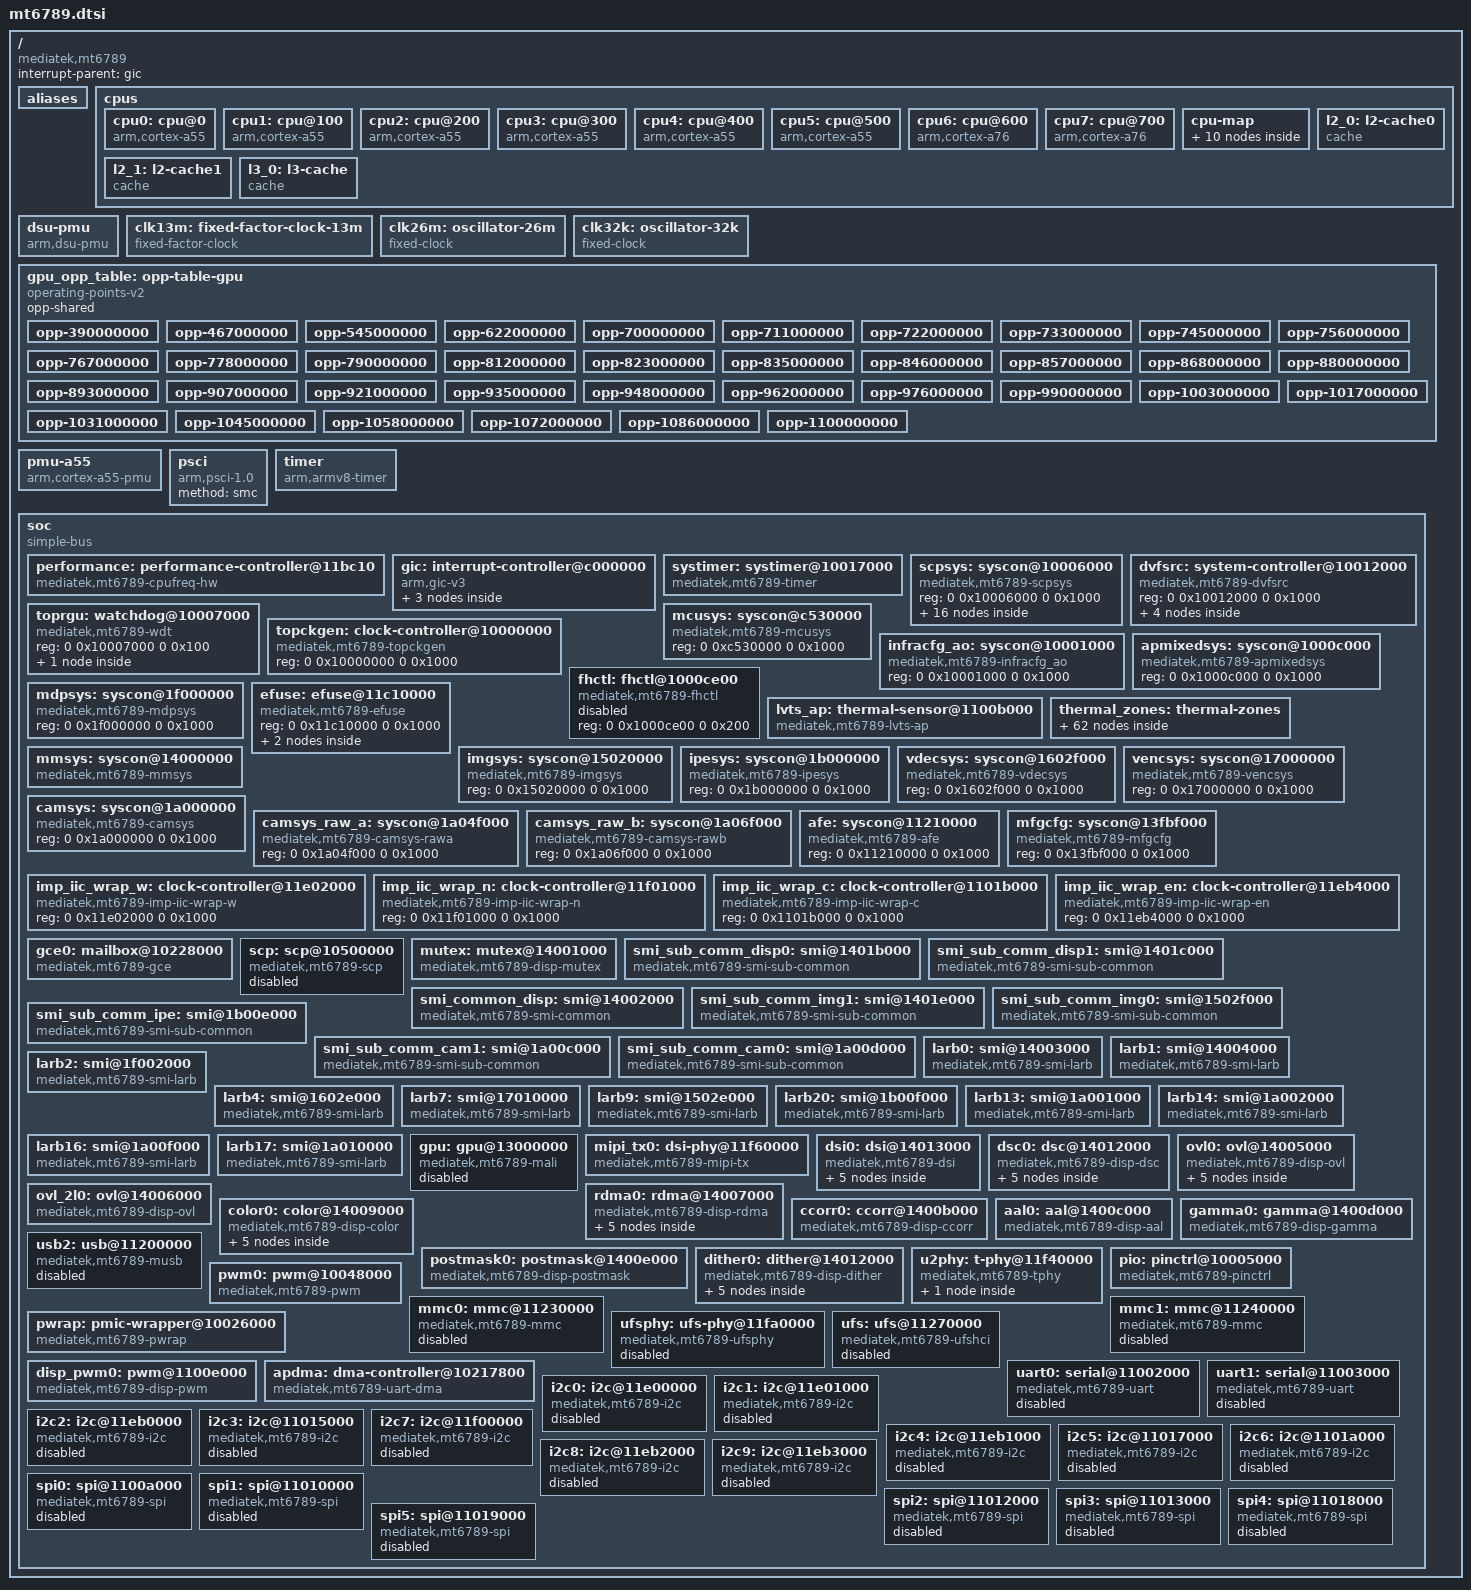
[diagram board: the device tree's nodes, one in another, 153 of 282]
// SPDX-License-Identifier: GPL-2.0
/*
 * Device Tree Source for Mediatek MT6789
 *
 * Copyright (c) 2025 Arseniy Velikanov <me@adomerle.pw>
 */
#include <dt-bindings/interrupt-controller/arm-gic.h>
#include <dt-bindings/interrupt-controller/irq.h>
#include <dt-bindings/phy/phy.h>

#include <dt-bindings/clock/mediatek,mt6789-clk.h>
#include <dt-bindings/power/mediatek,mt6789-power.h>
#include <dt-bindings/reset/mediatek,mt6789-resets.h>
#include <dt-bindings/gce/mediatek,mt6789-gce.h>
#include <dt-bindings/memory/mediatek,mt6789-memory-port.h>
#include <dt-bindings/thermal/thermal.h>
#include <dt-bindings/thermal/mediatek,lvts-thermal.h>

/ {
	compatible = "mediatek,mt6789";
	interrupt-parent = <&gic>;
	#address-cells = <2>;
	#size-cells = <2>;

	aliases {
		i2c0 = &i2c0;
		i2c1 = &i2c1;
		i2c2 = &i2c2;
		i2c3 = &i2c3;
		i2c4 = &i2c4;
		i2c5 = &i2c5;
		i2c6 = &i2c6;
		i2c7 = &i2c7;
		i2c8 = &i2c8;
		i2c9 = &i2c9;
	};

	cpus {
		#address-cells = <1>;
		#size-cells = <0>;

		cpu0: cpu@0 {
			device_type = "cpu";
			compatible = "arm,cortex-a55";
			reg = <0x000>;
			enable-method = "psci";
			clock-frequency = <2000000000>;
			capacity-dmips-mhz = <578>;
			performance-domains = <&performance 0>;
			i-cache-size = <32768>;
			i-cache-line-size = <64>;
			i-cache-sets = <128>;
			d-cache-size = <32768>;
			d-cache-line-size = <64>;
			d-cache-sets = <128>;
			next-level-cache = <&l2_0>;
			#cooling-cells = <2>;
		};

		cpu1: cpu@100 {
			device_type = "cpu";
			compatible = "arm,cortex-a55";
			reg = <0x100>;
			enable-method = "psci";
			clock-frequency = <2000000000>;
			capacity-dmips-mhz = <578>;
			performance-domains = <&performance 0>;
			i-cache-size = <32768>;
			i-cache-line-size = <64>;
			i-cache-sets = <128>;
			d-cache-size = <32768>;
			d-cache-line-size = <64>;
			d-cache-sets = <128>;
			next-level-cache = <&l2_0>;
			#cooling-cells = <2>;
		};

		cpu2: cpu@200 {
			device_type = "cpu";
			compatible = "arm,cortex-a55";
			reg = <0x200>;
			enable-method = "psci";
			clock-frequency = <2000000000>;
			capacity-dmips-mhz = <578>;
			performance-domains = <&performance 0>;
			i-cache-size = <32768>;
			i-cache-line-size = <64>;
			i-cache-sets = <128>;
			d-cache-size = <32768>;
			d-cache-line-size = <64>;
			d-cache-sets = <128>;
			next-level-cache = <&l2_0>;
			#cooling-cells = <2>;
		};

		cpu3: cpu@300 {
			device_type = "cpu";
			compatible = "arm,cortex-a55";
			reg = <0x300>;
			enable-method = "psci";
			clock-frequency = <2000000000>;
			capacity-dmips-mhz = <578>;
			performance-domains = <&performance 0>;
			i-cache-size = <32768>;
			i-cache-line-size = <64>;
			i-cache-sets = <128>;
			d-cache-size = <32768>;
			d-cache-line-size = <64>;
			d-cache-sets = <128>;
			next-level-cache = <&l2_0>;
			#cooling-cells = <2>;
		};

		cpu4: cpu@400 {
			device_type = "cpu";
			compatible = "arm,cortex-a55";
			reg = <0x400>;
			enable-method = "psci";
			clock-frequency = <2000000000>;
			capacity-dmips-mhz = <578>;
			performance-domains = <&performance 0>;
			i-cache-size = <32768>;
			i-cache-line-size = <64>;
			i-cache-sets = <128>;
			d-cache-size = <32768>;
			d-cache-line-size = <64>;
			d-cache-sets = <128>;
			next-level-cache = <&l2_0>;
			#cooling-cells = <2>;
		};

		cpu5: cpu@500 {
			device_type = "cpu";
			compatible = "arm,cortex-a55";
			reg = <0x500>;
			enable-method = "psci";
			clock-frequency = <2000000000>;
			capacity-dmips-mhz = <578>;
			performance-domains = <&performance 0>;
			i-cache-size = <32768>;
			i-cache-line-size = <64>;
			i-cache-sets = <128>;
			d-cache-size = <32768>;
			d-cache-line-size = <64>;
			d-cache-sets = <128>;
			next-level-cache = <&l2_0>;
			#cooling-cells = <2>;
		};

		cpu6: cpu@600 {
			device_type = "cpu";
			compatible = "arm,cortex-a76";
			reg = <0x600>;
			enable-method = "psci";
			clock-frequency = <2200000000>;
			capacity-dmips-mhz = <1024>;
			performance-domains = <&performance 1>;
			i-cache-size = <65536>;
			i-cache-line-size = <64>;
			i-cache-sets = <256>;
			d-cache-size = <65536>;
			d-cache-line-size = <64>;
			d-cache-sets = <256>;
			next-level-cache = <&l2_1>;
			#cooling-cells = <2>;
		};

		cpu7: cpu@700 {
			device_type = "cpu";
			compatible = "arm,cortex-a76";
			reg = <0x700>;
			enable-method = "psci";
			clock-frequency = <2200000000>;
			capacity-dmips-mhz = <1024>;
			performance-domains = <&performance 1>;
			i-cache-size = <65536>;
			i-cache-line-size = <64>;
			i-cache-sets = <256>;
			d-cache-size = <65536>;
			d-cache-line-size = <64>;
			d-cache-sets = <256>;
			next-level-cache = <&l2_1>;
			#cooling-cells = <2>;
		};

		cpu-map {
			cluster0 {
				core0 {
					cpu = <&cpu0>;
				};

				core1 {
					cpu = <&cpu1>;
				};

				core2 {
					cpu = <&cpu2>;
				};

				core3 {
					cpu = <&cpu3>;
				};
				core4 {
					cpu = <&cpu4>;
				};

				core5 {
					cpu = <&cpu5>;
				};
			};

			cluster1 {
				core0 {
					cpu = <&cpu6>;
				};

				core1 {
					cpu = <&cpu7>;
				};
			};
		};

		l2_0: l2-cache0 {
			compatible = "cache";
			cache-level = <2>;
			cache-size = <131072>;
			cache-line-size = <64>;
			cache-sets = <512>;
			next-level-cache = <&l3_0>;
			cache-unified;
		};

		l2_1: l2-cache1 {
			compatible = "cache";
			cache-level = <2>;
			cache-size = <262144>;
			cache-line-size = <64>;
			cache-sets = <512>;
			next-level-cache = <&l3_0>;
			cache-unified;
		};

		l3_0: l3-cache {
			compatible = "cache";
			cache-level = <3>;
			cache-size = <1048576>;
			cache-line-size = <64>;
			cache-sets = <1024>;
			cache-unified;
		};
	};

	dsu-pmu {
		compatible = "arm,dsu-pmu";
		interrupts = <GIC_SPI 18 IRQ_TYPE_LEVEL_HIGH &ppi_cluster0>;
		cpus = <&cpu0>, <&cpu1>, <&cpu2>, <&cpu3>,
		       <&cpu4>, <&cpu5>, <&cpu6>, <&cpu7>;
	};

	clk13m: fixed-factor-clock-13m {
		compatible = "fixed-factor-clock";
		#clock-cells = <0>;
		clocks = <&clk26m>;
		clock-div = <2>;
		clock-mult = <1>;
		clock-output-names = "clk13m";
	};

	clk26m: oscillator-26m {
		compatible = "fixed-clock";
		#clock-cells = <0>;
		clock-frequency = <26000000>;
		clock-output-names = "clk26m";
	};

	clk32k: oscillator-32k {
		compatible = "fixed-clock";
		#clock-cells = <0>;
		clock-frequency = <32768>;
		clock-output-names = "clk32k";
	};

	gpu_opp_table: opp-table-gpu {
		compatible = "operating-points-v2";
		opp-shared;

		opp-390000000 {
			opp-hz = /bits/ 64 <390000000>;
			opp-microvolt = <675000>;
		};
		opp-467000000 {
			opp-hz = /bits/ 64 <467000000>;
			opp-microvolt = <681250>;
		};
		opp-545000000 {
			opp-hz = /bits/ 64 <545000000>;
			opp-microvolt = <687500>;
		};
		opp-622000000 {
			opp-hz = /bits/ 64 <622000000>;
			opp-microvolt = <693750>;
		};
		opp-700000000 {
			opp-hz = /bits/ 64 <700000000>;
			opp-microvolt = <700000>;
		};
		opp-711000000 {
			opp-hz = /bits/ 64 <711000000>;
			opp-microvolt = <706250>;
		};
		opp-722000000 {
			opp-hz = /bits/ 64 <722000000>;
			opp-microvolt = <712500>;
		};
		opp-733000000 {
			opp-hz = /bits/ 64 <733000000>;
			opp-microvolt = <718750>;
		};
		opp-745000000 {
			opp-hz = /bits/ 64 <745000000>;
			opp-microvolt = <725000>;
		};
		opp-756000000 {
			opp-hz = /bits/ 64 <756000000>;
			opp-microvolt = <731250>;
		};
		opp-767000000 {
			opp-hz = /bits/ 64 <767000000>;
			opp-microvolt = <737500>;
		};
		opp-778000000 {
			opp-hz = /bits/ 64 <778000000>;
			opp-microvolt = <743750>;
		};
		opp-790000000 {
			opp-hz = /bits/ 64 <790000000>;
			opp-microvolt = <750000>;
		};
		opp-812000000 {
			opp-hz = /bits/ 64 <812000000>;
			opp-microvolt = <756250>;
		};
		opp-823000000 {
			opp-hz = /bits/ 64 <823000000>;
			opp-microvolt = <762500>;
		};
		opp-835000000 {
			opp-hz = /bits/ 64 <835000000>;
			opp-microvolt = <768750>;
		};
		opp-846000000 {
			opp-hz = /bits/ 64 <846000000>;
			opp-microvolt = <775000>;
		};
		opp-857000000 {
			opp-hz = /bits/ 64 <857000000>;
			opp-microvolt = <781250>;
		};
		opp-868000000 {
			opp-hz = /bits/ 64 <868000000>;
			opp-microvolt = <787500>;
		};
		opp-880000000 {
			opp-hz = /bits/ 64 <880000000>;
			opp-microvolt = <793750>;
		};
		opp-893000000 {
			opp-hz = /bits/ 64 <893000000>;
			opp-microvolt = <800000>;
		};
		opp-907000000 {
			opp-hz = /bits/ 64 <907000000>;
			opp-microvolt = <806250>;
		};
		opp-921000000 {
			opp-hz = /bits/ 64 <921000000>;
			opp-microvolt = <812500>;
		};
		opp-935000000 {
			opp-hz = /bits/ 64 <935000000>;
			opp-microvolt = <818750>;
		};
		opp-948000000 {
			opp-hz = /bits/ 64 <948000000>;
			opp-microvolt = <825000>;
		};
		opp-962000000 {
			opp-hz = /bits/ 64 <962000000>;
			opp-microvolt = <831250>;
		};
		opp-976000000 {
			opp-hz = /bits/ 64 <976000000>;
			opp-microvolt = <843750>;
		};
		opp-990000000 {
			opp-hz = /bits/ 64 <990000000>;
			opp-microvolt = <850000>;
		};
		opp-1003000000 {
			opp-hz = /bits/ 64 <1003000000>;
			opp-microvolt = <856250>;
		};
		opp-1017000000 {
			opp-hz = /bits/ 64 <1017000000>;
			opp-microvolt = <862500>;
		};
		opp-1031000000 {
			opp-hz = /bits/ 64 <1031000000>;
			opp-microvolt = <868750>;
		};
		opp-1045000000 {
			opp-hz = /bits/ 64 <1045000000>;
			opp-microvolt = <875000>;
		};
		opp-1058000000 {
			opp-hz = /bits/ 64 <1058000000>;
			opp-microvolt = <881250>;
		};
		opp-1072000000 {
			opp-hz = /bits/ 64 <1072000000>;
			opp-microvolt = <887500>;
		};
		opp-1086000000 {
			opp-hz = /bits/ 64 <1086000000>;
			opp-microvolt = <893750>;
		};
		opp-1100000000 {
			opp-hz = /bits/ 64 <1100000000>;
			opp-microvolt = <900000>;
		};
	};

	pmu-a55 {
		compatible = "arm,cortex-a55-pmu";
		interrupt-parent = <&gic>;
		interrupts = <GIC_PPI 7 IRQ_TYPE_LEVEL_HIGH &ppi_cluster0>;
	};

	/*
	pmu-a76 {
		compatible = "arm,cortex-a76-pmu";
		interrupt-parent = <&gic>;
		interrupts = <GIC_PPI 7 IRQ_TYPE_LEVEL_HIGH &ppi_cluster1>;
	};*/

	psci {
		compatible = "arm,psci-1.0";
		method = "smc";
	};

	timer: timer {
		compatible = "arm,armv8-timer";
		interrupt-parent = <&gic>;
		interrupts = <GIC_PPI 13 IRQ_TYPE_LEVEL_HIGH &ppi_cluster0>,
		             <GIC_PPI 14 IRQ_TYPE_LEVEL_HIGH &ppi_cluster0>,
		             <GIC_PPI 11 IRQ_TYPE_LEVEL_HIGH &ppi_cluster0>,
		             <GIC_PPI 10 IRQ_TYPE_LEVEL_HIGH &ppi_cluster0>;
	};

	soc {
		#address-cells = <2>;
		#size-cells = <2>;
		compatible = "simple-bus";
		ranges;

		performance: performance-controller@11bc10 {
			compatible = "mediatek,mt6789-cpufreq-hw";
			reg = <0 0x0011bc10 0 0x120>, <0 0x0011bd30 0 0x120>;
			#performance-domain-cells = <1>;
		};

		gic: interrupt-controller@c000000 {
			compatible = "arm,gic-v3";
			#interrupt-cells = <4>;
			#redistributor-regions = <1>;
			interrupt-parent = <&gic>;
			interrupt-controller;
			reg = <0 0x0c000000 0 0x40000>,
			      <0 0x0c040000 0 0x200000>;
			interrupts = <GIC_PPI 9 IRQ_TYPE_LEVEL_HIGH &ppi_cluster0>;

			ppi-partitions {
				ppi_cluster0: interrupt-partition-0 {
					affinity = <&cpu0 &cpu1 &cpu2 &cpu3 &cpu4 &cpu5>;
				};

				ppi_cluster1: interrupt-partition-1 {
					affinity = <&cpu6 &cpu7>;
				};
			};
		};

		systimer: systimer@10017000 {
			compatible = "mediatek,mt6789-timer",
			             "mediatek,mt6765-timer";
			reg = <0 0x10017000 0 0x1000>;
			interrupts = <GIC_SPI 265 IRQ_TYPE_LEVEL_HIGH &ppi_cluster0>;
			clocks = <&clk13m>;
		};

		scpsys: syscon@10006000 {
			compatible = "mediatek,mt6789-scpsys", "syscon", "simple-mfd";
			reg = <0 0x10006000 0 0x1000>;

			/* System Power Manager */
			spm: power-controller {
				compatible = "mediatek,mt6789-power-controller";
				#address-cells = <1>;
				#size-cells = <0>;
				#power-domain-cells = <1>;

				/* power domain of the SoC */
				power-domain@MT6789_POWER_DOMAIN_AUDIO {
					reg = <MT6789_POWER_DOMAIN_AUDIO>;
					clocks = <&topckgen CLK_TOP_AUD_INTBUS_SEL>,
					         <&infracfg_ao CLK_IFRAO_AUDIO_26M_BCLK>,
					         <&infracfg_ao CLK_IFRAO_AUDIO>;
					clock-names = "audio", "audio1", "audio2";
					mediatek,infracfg = <&infracfg_ao>;
					#power-domain-cells = <0>;
				};

				power-domain@MT6789_POWER_DOMAIN_MD {
					reg = <MT6789_POWER_DOMAIN_MD>;
					mediatek,infracfg = <&infracfg_ao>;
					#address-cells = <1>;
					#size-cells = <0>;
					#power-domain-cells = <1>;
				};

				power-domain@MT6789_POWER_DOMAIN_CONN {
					reg = <MT6789_POWER_DOMAIN_CONN>;
					mediatek,infracfg = <&infracfg_ao>;
					#address-cells = <1>;
					#size-cells = <0>;
					#power-domain-cells = <1>;
				};

				mfg0: power-domain@MT6789_POWER_DOMAIN_MFG0 {
					reg = <MT6789_POWER_DOMAIN_MFG0>;
					#address-cells = <1>;
					#size-cells = <0>;
					#power-domain-cells = <1>;

					mfg1: power-domain@MT6789_POWER_DOMAIN_MFG1 {
						reg = <MT6789_POWER_DOMAIN_MFG1>;
						clocks = <&topckgen CLK_TOP_MFG_PLL_SEL>,
						         <&topckgen CLK_TOP_MFG_REF_SEL>;
						clock-names = "mfg", "alt";
						mediatek,infracfg = <&infracfg_ao>;
						#address-cells = <1>;
						#size-cells = <0>;
						#power-domain-cells = <1>;

						mfg2: power-domain@MT6789_POWER_DOMAIN_MFG2 {
							reg = <MT6789_POWER_DOMAIN_MFG2>;
							clocks = <&mfgcfg CLK_MFGCFG_BG3D>;
							clock-names = "mfg";
							#power-domain-cells = <0>;
						};

						power-domain@MT6789_POWER_DOMAIN_MFG3 {
							reg = <MT6789_POWER_DOMAIN_MFG3>;
							#power-domain-cells = <0>;
						};
					};
				};

				disp: power-domain@MT6789_POWER_DOMAIN_DISP {
					reg = <MT6789_POWER_DOMAIN_DISP>;
					clocks = <&topckgen CLK_TOP_DISP_SEL>,
					         <&mdpsys CLK_MDP_SMI0>,
					         <&mmsys CLK_MM_SMI_INFRA>,
					         <&mmsys CLK_MM_SMI_COMMON>,
					         <&mmsys CLK_MM_SMI_GALS>,
					         <&mmsys CLK_MM_SMI_IOMMU>,
					         <&topckgen CLK_TOP_MDP_SEL>;
					clock-names = "disp", "disp-0", "disp-1", "disp-2",
								  "disp-3", "disp-4", "mdp";
					mediatek,infracfg = <&infracfg_ao>;
					#address-cells = <1>;
					#size-cells = <0>;
					#power-domain-cells = <1>;

					power-domain@MT6789_POWER_DOMAIN_IPE {
						reg = <MT6789_POWER_DOMAIN_IPE>;
						clocks = <&topckgen CLK_TOP_IPE_SEL>,
						         <&ipesys CLK_IPE_SMI_SUBCOM>,
						         <&ipesys CLK_IPE_GALS>,
						         <&ipesys CLK_IPE_LARB19>,
						         <&ipesys CLK_IPE_LARB20>;
						clock-names = "ipe", "ipe-0", "ipe-1", "ipe-2",
									  "ipe-3";
						mediatek,infracfg = <&infracfg_ao>;
						#power-domain-cells = <0>;
					};

					power-domain@MT6789_POWER_DOMAIN_ISP {
						reg = <MT6789_POWER_DOMAIN_ISP>;
						clocks = <&topckgen CLK_TOP_IMG1_SEL>,
						         <&imgsys CLK_IMGSYS_GALS>,
						         <&imgsys CLK_IMGSYS_LARB9>;
						clock-names = "isp", "isp-0", "isp-1";
						mediatek,infracfg = <&infracfg_ao>;
						#power-domain-cells = <0>;
					};

					power-domain@MT6789_POWER_DOMAIN_VENC {
						reg = <MT6789_POWER_DOMAIN_VENC>;
						clocks = <&topckgen CLK_TOP_VENC_SEL>,
						         <&vencsys CLK_VEN1_CKE1_VENC>;
						clock-names = "venc", "venc-0";
						mediatek,infracfg = <&infracfg_ao>;
						#power-domain-cells = <0>;
					};

					power-domain@MT6789_POWER_DOMAIN_VDEC {
						reg = <MT6789_POWER_DOMAIN_VDEC>;
						clocks = <&topckgen CLK_TOP_VDEC_SEL>,
						         <&vdecsys CLK_VDE2_VDEC_CKEN>,
						         <&vdecsys CLK_VDE2_LARB1_CKEN>;
						clock-names = "vdec", "vdec-0", "vdec-1";
						mediatek,infracfg = <&infracfg_ao>;
						#address-cells = <1>;
						#size-cells = <0>;
						#power-domain-cells = <1>;
					};

					power-domain@MT6789_POWER_DOMAIN_CAM {
						reg = <MT6789_POWER_DOMAIN_CAM>;
						clocks = <&topckgen CLK_TOP_CAM_SEL>,
						         <&camsys CLK_CAM_M_LARB13>,
						         <&camsys CLK_CAM_M_LARB14>;
						clock-names = "cam", "cam-0", "cam-1";
						mediatek,infracfg = <&infracfg_ao>;
						#address-cells = <1>;
						#size-cells = <0>;
						#power-domain-cells = <1>;

						power-domain@MT6789_POWER_DOMAIN_CAM_RAWA {
							reg = <MT6789_POWER_DOMAIN_CAM_RAWA>;
							clocks = <&camsys_raw_a CLK_CAM_RA_LARBX>;
							clock-names = "cam_rawa-0";
							#power-domain-cells = <0>;
						};

						power-domain@MT6789_POWER_DOMAIN_CAM_RAWB {
							reg = <MT6789_POWER_DOMAIN_CAM_RAWB>;
							clocks = <&camsys_raw_b CLK_CAM_RB_LARBX>;
							clock-names = "cam_rawb-0";
							#power-domain-cells = <0>;
						};
					};
				};
			};
		};

		dvfsrc: system-controller@10012000 {
			compatible = "mediatek,mt6789-dvfsrc";
			reg = <0 0x10012000 0 0x1000>;

			regulators {
				compatible = "mediatek,mt6789-dvfsrc-regulator";

				dvfsrc_vcore: dvfsrc-vcore {
					regulator-name = "dvfsrc-vcore";
					regulator-min-microvolt = <550000>;
					regulator-max-microvolt = <725000>;
					regulator-always-on;
				};

				dvfsrc_vscp: dvfsrc-vscp {
					regulator-name = "dvfsrc-vscp";
					regulator-min-microvolt = <550000>;
					regulator-max-microvolt = <725000>;
					regulator-always-on;
				};
			};

			emi_icc: interconnect {
				compatible = "mediatek,mt6789-emi";
				#interconnect-cells = <1>;
			};
		};

		toprgu: watchdog@10007000 {
			compatible = "mediatek,mt6789-wdt",
				     "mediatek,mt6589-wdt";
			reg = <0 0x10007000 0 0x100>;

			reboot-mode {
				compatible = "syscon-reboot-mode";
				offset = <0x24>;
				mask = <0xf>;
				mode-recovery = <2>;
				mode-bootloader = <3>;
			};
		};

		mcusys: syscon@c530000 {
			compatible = "mediatek,mt6789-mcusys", "syscon";
			reg = <0 0xc530000 0 0x1000>;
			#clock-cells = <1>;
		};

		topckgen: clock-controller@10000000 {
			compatible = "mediatek,mt6789-topckgen", "syscon";
			reg = <0 0x10000000 0 0x1000>;
			#clock-cells = <1>;
		};

		infracfg_ao: syscon@10001000 {
			compatible = "mediatek,mt6789-infracfg_ao", "syscon";
			reg = <0 0x10001000 0 0x1000>;
			#clock-cells = <1>;
			#reset-cells = <1>;
		};

		apmixedsys: syscon@1000c000 {
			compatible = "mediatek,mt6789-apmixedsys", "syscon";
			reg = <0 0x1000c000 0 0x1000>;
			#clock-cells = <1>;
		};

		fhctl: fhctl@1000ce00 {
			compatible = "mediatek,mt6789-fhctl";
			reg = <0 0x1000ce00 0 0x200>;
			status = "disabled";
		};

		mdpsys: syscon@1f000000 {
			compatible = "mediatek,mt6789-mdpsys", "syscon";
			reg = <0 0x1f000000 0 0x1000>;
			#clock-cells = <1>;
		};

		efuse: efuse@11c10000 {
			compatible = "mediatek,mt6789-efuse", "mediatek,efuse";
			reg = <0 0x11c10000 0 0x1000>;
			#address-cells = <1>;
			#size-cells = <1>;

			lvts_efuse_data1: lvts1-calib {
				reg = <0x1b4 0x2c>;
			};

			lvts_efuse_data2: lvts2-calib {
				reg = <0x2f8 0x8>;
			};
		};

		lvts_ap: thermal-sensor@1100b000 {
			compatible = "mediatek,mt6789-lvts-ap";
			reg = <0 0x1100b000 0 0xc00>;
			interrupts = <GIC_SPI 201 IRQ_TYPE_LEVEL_HIGH &ppi_cluster0>;
			clocks = <&infracfg_ao CLK_IFRAO_THERM>;
			resets = <&infracfg_ao MT6789_INFRA_RST0_LVTS_AP_SWRST>;

			nvmem-cells = <&lvts_efuse_data1 &lvts_efuse_data2>;
			nvmem-cell-names = "lvts-calib-data-1", "lvts-calib-data-2";

			#thermal-sensor-cells = <1>;
		};

		thermal_zones: thermal-zones {
			gpu0-thermal {
				polling-delay = <1000>;
				polling-delay-passive = <250>;
				thermal-sensors = <&lvts_ap MT6789_AP_GPU0>;

				trips {
					gpu0_alert0: trip-alert0 {
						temperature = <85000>;
						hysteresis = <2000>;
						type = "passive";
					};

					gpu0_alert1: trip-alert1 {
						temperature = <95000>;
						hysteresis = <2000>;
						type = "hot";
					};

					gpu0_crit: trip-crit {
						temperature = <100000>;
						hysteresis = <0>;
						type = "critical";
					};
				};

				cooling-maps {
					map0 {
						trip = <&gpu0_alert0>;
						cooling-device = <&gpu THERMAL_NO_LIMIT THERMAL_NO_LIMIT>;
					};
				};
			};

			gpu1-thermal {
				polling-delay = <1000>;
				polling-delay-passive = <250>;
				thermal-sensors = <&lvts_ap MT6789_AP_GPU1>;

				trips {
					gpu1_alert0: trip-alert0 {
						temperature = <85000>;
						hysteresis = <2000>;
						type = "passive";
					};

					gpu1_alert1: trip-alert1 {
						temperature = <95000>;
						hysteresis = <2000>;
						type = "hot";
					};

					gpu1_crit: trip-crit {
						temperature = <100000>;
						hysteresis = <0>;
						type = "critical";
					};
				};

				cooling-maps {
					map0 {
						trip = <&gpu1_alert0>;
						cooling-device = <&gpu THERMAL_NO_LIMIT THERMAL_NO_LIMIT>;
					};
				};
			};

			cpu0-thermal {
				polling-delay = <1000>;
				polling-delay-passive = <250>;
				thermal-sensors = <&lvts_ap MT6789_AP_LITTLE_CPU0>;

				trips {
					cpu0_alert: trip-alert {
						temperature = <85000>;
						hysteresis = <2000>;
						type = "passive";
					};

					cpu0_crit: trip-crit {
						temperature = <100000>;
						hysteresis = <2000>;
						type = "critical";
					};
				};

				cooling-maps {
					map0 {
						trip = <&cpu0_alert>;
						cooling-device = <&cpu0 THERMAL_NO_LIMIT THERMAL_NO_LIMIT>,
									<&cpu1 THERMAL_NO_LIMIT THERMAL_NO_LIMIT>,
									<&cpu2 THERMAL_NO_LIMIT THERMAL_NO_LIMIT>,
									<&cpu3 THERMAL_NO_LIMIT THERMAL_NO_LIMIT>,
									<&cpu4 THERMAL_NO_LIMIT THERMAL_NO_LIMIT>,
									<&cpu5 THERMAL_NO_LIMIT THERMAL_NO_LIMIT>;
					};
				};
			};

			cpu1-thermal {
				polling-delay = <1000>;
				polling-delay-passive = <250>;
				thermal-sensors = <&lvts_ap MT6789_AP_LITTLE_CPU1>;

				trips {
					cpu1_alert: trip-alert {
						temperature = <85000>;
						hysteresis = <2000>;
						type = "passive";
					};

					cpu1_crit: trip-crit {
						temperature = <100000>;
						hysteresis = <2000>;
						type = "critical";
					};
				};

				cooling-maps {
					map0 {
						trip = <&cpu1_alert>;
						cooling-device = <&cpu0 THERMAL_NO_LIMIT THERMAL_NO_LIMIT>,
									<&cpu1 THERMAL_NO_LIMIT THERMAL_NO_LIMIT>,
									<&cpu2 THERMAL_NO_LIMIT THERMAL_NO_LIMIT>,
									<&cpu3 THERMAL_NO_LIMIT THERMAL_NO_LIMIT>,
									<&cpu4 THERMAL_NO_LIMIT THERMAL_NO_LIMIT>,
									<&cpu5 THERMAL_NO_LIMIT THERMAL_NO_LIMIT>;
					};
				};
			};

			cpu2-thermal {
				polling-delay = <1000>;
				polling-delay-passive = <250>;
				thermal-sensors = <&lvts_ap MT6789_AP_LITTLE_CPU2>;

				trips {
					cpu2_alert: trip-alert {
						temperature = <85000>;
						hysteresis = <2000>;
						type = "passive";
					};

					cpu2_crit: trip-crit {
						temperature = <100000>;
						hysteresis = <2000>;
						type = "critical";
					};
				};

				cooling-maps {
					map0 {
						trip = <&cpu2_alert>;
						cooling-device = <&cpu0 THERMAL_NO_LIMIT THERMAL_NO_LIMIT>,
									<&cpu1 THERMAL_NO_LIMIT THERMAL_NO_LIMIT>,
									<&cpu2 THERMAL_NO_LIMIT THERMAL_NO_LIMIT>,
									<&cpu3 THERMAL_NO_LIMIT THERMAL_NO_LIMIT>,
									<&cpu4 THERMAL_NO_LIMIT THERMAL_NO_LIMIT>,
									<&cpu5 THERMAL_NO_LIMIT THERMAL_NO_LIMIT>;
					};
				};
			};

			cpu3-thermal {
				polling-delay = <1000>;
				polling-delay-passive = <250>;
				thermal-sensors = <&lvts_ap MT6789_AP_LITTLE_CPU3>;

				trips {
					cpu3_alert: trip-alert {
						temperature = <85000>;
						hysteresis = <2000>;
						type = "passive";
					};

					cpu3_crit: trip-crit {
						temperature = <100000>;
						hysteresis = <2000>;
						type = "critical";
					};
				};

				cooling-maps {
					map0 {
						trip = <&cpu3_alert>;
						cooling-device = <&cpu0 THERMAL_NO_LIMIT THERMAL_NO_LIMIT>,
									<&cpu1 THERMAL_NO_LIMIT THERMAL_NO_LIMIT>,
									<&cpu2 THERMAL_NO_LIMIT THERMAL_NO_LIMIT>,
									<&cpu3 THERMAL_NO_LIMIT THERMAL_NO_LIMIT>,
									<&cpu4 THERMAL_NO_LIMIT THERMAL_NO_LIMIT>,
									<&cpu5 THERMAL_NO_LIMIT THERMAL_NO_LIMIT>;
					};
				};
			};

			cpu4-thermal {
				polling-delay = <1000>;
				polling-delay-passive = <250>;
				thermal-sensors = <&lvts_ap MT6789_AP_LITTLE_CPU4>;

				trips {
					cpu4_alert: trip-alert {
						temperature = <85000>;
						hysteresis = <2000>;
						type = "passive";
					};

					cpu4_crit: trip-crit {
						temperature = <100000>;
						hysteresis = <2000>;
						type = "critical";
					};
				};

				cooling-maps {
					map0 {
						trip = <&cpu4_alert>;
						cooling-device = <&cpu0 THERMAL_NO_LIMIT THERMAL_NO_LIMIT>,
									<&cpu1 THERMAL_NO_LIMIT THERMAL_NO_LIMIT>,
									<&cpu2 THERMAL_NO_LIMIT THERMAL_NO_LIMIT>,
									<&cpu3 THERMAL_NO_LIMIT THERMAL_NO_LIMIT>,
									<&cpu4 THERMAL_NO_LIMIT THERMAL_NO_LIMIT>,
									<&cpu5 THERMAL_NO_LIMIT THERMAL_NO_LIMIT>;
					};
				};
			};

			cpu5-thermal {
				polling-delay = <1000>;
				polling-delay-passive = <250>;
				thermal-sensors = <&lvts_ap MT6789_AP_LITTLE_CPU5>;

				trips {
					cpu5_alert: trip-alert {
						temperature = <85000>;
						hysteresis = <2000>;
						type = "passive";
					};

					cpu5_crit: trip-crit {
						temperature = <100000>;
						hysteresis = <2000>;
						type = "critical";
					};
				};

				cooling-maps {
					map0 {
						trip = <&cpu5_alert>;
						cooling-device = <&cpu0 THERMAL_NO_LIMIT THERMAL_NO_LIMIT>,
									<&cpu1 THERMAL_NO_LIMIT THERMAL_NO_LIMIT>,
									<&cpu2 THERMAL_NO_LIMIT THERMAL_NO_LIMIT>,
									<&cpu3 THERMAL_NO_LIMIT THERMAL_NO_LIMIT>,
									<&cpu4 THERMAL_NO_LIMIT THERMAL_NO_LIMIT>,
									<&cpu5 THERMAL_NO_LIMIT THERMAL_NO_LIMIT>;
					};
				};
			};

			cpu6-thermal {
				polling-delay = <1000>;
				polling-delay-passive = <250>;
				thermal-sensors = <&lvts_ap MT6789_AP_BIG_CPU0>;

				trips {
					cpu6_alert: trip-alert {
						temperature = <85000>;
						hysteresis = <2000>;
						type = "passive";
					};

					cpu6_crit: trip-crit {
						temperature = <100000>;
						hysteresis = <2000>;
						type = "critical";
					};
				};

				cooling-maps {
					map0 {
						trip = <&cpu6_alert>;
						cooling-device = <&cpu6 THERMAL_NO_LIMIT THERMAL_NO_LIMIT>,
									<&cpu7 THERMAL_NO_LIMIT THERMAL_NO_LIMIT>;
					};
				};
			};

			cpu7-thermal {
				polling-delay = <1000>;
				polling-delay-passive = <250>;
				thermal-sensors = <&lvts_ap MT6789_AP_BIG_CPU1>;

				trips {
					cpu7_alert: trip-alert {
						temperature = <85000>;
						hysteresis = <2000>;
						type = "passive";
					};

					cpu7_crit: trip-crit {
						temperature = <100000>;
						hysteresis = <2000>;
						type = "critical";
					};
				};

				cooling-maps {
					map0 {
						trip = <&cpu7_alert>;
						cooling-device = <&cpu6 THERMAL_NO_LIMIT THERMAL_NO_LIMIT>,
									<&cpu7 THERMAL_NO_LIMIT THERMAL_NO_LIMIT>;
					};
				};
			};
		};

		mmsys: syscon@14000000 {
			compatible = "mediatek,mt6789-mmsys", "syscon";
			reg = <0 0x14000000 0 0x1000>;
			#clock-cells = <1>;
			mediatek,gce-client-reg = <&gce0 SUBSYS_1400XXXX 0x0000 0x1000>;
		};

		imgsys: syscon@15020000 {
			compatible = "mediatek,mt6789-imgsys", "syscon";
			reg = <0 0x15020000 0 0x1000>;
			#clock-cells = <1>;
		};

		ipesys: syscon@1b000000 {
			compatible = "mediatek,mt6789-ipesys", "syscon";
			reg = <0 0x1b000000 0 0x1000>;
			#clock-cells = <1>;
		};

		vdecsys: syscon@1602f000 {
			compatible = "mediatek,mt6789-vdecsys", "syscon";
			reg = <0 0x1602f000 0 0x1000>;
			#clock-cells = <1>;
		};

		vencsys: syscon@17000000 {
			compatible = "mediatek,mt6789-vencsys", "syscon";
			reg = <0 0x17000000 0 0x1000>;
			#clock-cells = <1>;
		};

		camsys: syscon@1a000000 {
			compatible = "mediatek,mt6789-camsys", "syscon";
			reg = <0 0x1a000000 0 0x1000>;
			#clock-cells = <1>;
		};

		camsys_raw_a: syscon@1a04f000 {
			compatible = "mediatek,mt6789-camsys-rawa", "syscon";
			reg = <0 0x1a04f000 0 0x1000>;
			#clock-cells = <1>;
		};

		camsys_raw_b: syscon@1a06f000 {
			compatible = "mediatek,mt6789-camsys-rawb", "syscon";
			reg = <0 0x1a06f000 0 0x1000>;
			#clock-cells = <1>;
		};

		afe: syscon@11210000 {
			compatible = "mediatek,mt6789-afe", "syscon";
			reg = <0 0x11210000 0 0x1000>;
			#clock-cells = <1>;
		};

		mfgcfg: syscon@13fbf000 {
			compatible = "mediatek,mt6789-mfgcfg", "syscon";
			reg = <0 0x13fbf000 0 0x1000>;
			#clock-cells = <1>;
		};

		imp_iic_wrap_w: clock-controller@11e02000 {
			compatible = "mediatek,mt6789-imp-iic-wrap-w";
			reg = <0 0x11e02000 0 0x1000>;
			#clock-cells = <1>;
		};

		imp_iic_wrap_n: clock-controller@11f01000 {
			compatible = "mediatek,mt6789-imp-iic-wrap-n";
			reg = <0 0x11f01000 0 0x1000>;
			#clock-cells = <1>;
		};

		imp_iic_wrap_c: clock-controller@1101b000 {
			compatible = "mediatek,mt6789-imp-iic-wrap-c";
			reg = <0 0x1101b000 0 0x1000>;
			#clock-cells = <1>;
		};

		imp_iic_wrap_en: clock-controller@11eb4000 {
			compatible = "mediatek,mt6789-imp-iic-wrap-en";
			reg = <0 0x11eb4000 0 0x1000>;
			#clock-cells = <1>;
		};

		gce0: mailbox@10228000 {
			compatible = "mediatek,mt6789-gce";
			reg = <0 0x10228000 0 0x4000>;
			interrupts = <GIC_SPI 235 IRQ_TYPE_LEVEL_HIGH &ppi_cluster0>;
			#mbox-cells = <2>;
			clocks = <&infracfg_ao CLK_IFRAO_GCE>;
			clock-names = "gce";
		};

		scp: scp@10500000 {
			compatible = "mediatek,mt6789-scp",
			             "mediatek,mt8192-scp";
			reg = <0 0x10500000 0 0x100000>,
			      <0 0x10720000 0 0xe0000>,
			      <0 0x10700000 0 0x8000>;
			reg-names = "sram", "cfg", "l1tcm";
			interrupts = <GIC_SPI 466 IRQ_TYPE_LEVEL_HIGH &ppi_cluster0>;
			status = "disabled";
		};

		mutex: mutex@14001000 {
			compatible = "mediatek,mt6789-disp-mutex";
			reg = <0 0x14001000 0 0x1000>;
			interrupts = <GIC_SPI 285 IRQ_TYPE_LEVEL_HIGH &ppi_cluster0>;
			power-domains = <&spm MT6789_POWER_DOMAIN_DISP>;
			clocks = <&mmsys CLK_MM_DISP_MUTEX0>;
			mediatek,gce-client-reg = <&gce0 SUBSYS_1400XXXX 0x1000 0x1000>;
		};

		smi_sub_comm_disp0: smi@1401b000 {
			compatible = "mediatek,mt6789-smi-sub-common";
			reg = <0 0x1401b000 0 0x1000>;
			power-domains = <&spm MT6789_POWER_DOMAIN_DISP>;
			clocks = <&mmsys CLK_MM_SMI_INFRA>,
			         <&mmsys CLK_MM_SMI_COMMON>,
			         <&mmsys CLK_MM_SMI_GALS>,
			         <&mmsys CLK_MM_SMI_IOMMU>;
			mediatek,smi = <&smi_common_disp>;
			clock-names = "apb", "smi", "gals0", "gals1";
		};

		smi_sub_comm_disp1: smi@1401c000 {
			compatible = "mediatek,mt6789-smi-sub-common";
			reg = <0 0x1401c000 0 0x1000>;
			power-domains = <&spm MT6789_POWER_DOMAIN_DISP>;
			clocks = <&mmsys CLK_MM_SMI_INFRA>,
			         <&mmsys CLK_MM_SMI_COMMON>,
			         <&mmsys CLK_MM_SMI_GALS>,
			         <&mmsys CLK_MM_SMI_IOMMU>;
			mediatek,smi = <&smi_common_disp>;
			clock-names = "apb", "smi", "gals0", "gals1";
		};

		smi_common_disp: smi@14002000 {
			compatible = "mediatek,mt6789-smi-common";
			reg = <0 0x14002000 0 0x1000>;
			clocks = <&mmsys CLK_MM_SMI_INFRA>,
			         <&mmsys CLK_MM_SMI_COMMON>,
			         <&mmsys CLK_MM_SMI_GALS>,
			         <&mmsys CLK_MM_SMI_IOMMU>;
			clock-names = "apb", "smi", "gals0", "gals1";
			power-domains = <&spm MT6789_POWER_DOMAIN_DISP>;
		};

		smi_sub_comm_img1: smi@1401e000 {
			compatible = "mediatek,mt6789-smi-sub-common";
			reg = <0 0x1401e000 0 0x1000>;
			mediatek,smi = <&smi_common_disp>;
			power-domains = <&spm MT6789_POWER_DOMAIN_DISP>;
			clocks = <&mmsys CLK_MM_SMI_INFRA>,
			         <&mmsys CLK_MM_SMI_COMMON>,
			         <&mmsys CLK_MM_SMI_GALS>,
			         <&mmsys CLK_MM_SMI_IOMMU>;
			clock-names = "apb", "smi", "gals0", "gals1";
		};

		smi_sub_comm_img0: smi@1502f000 {
			compatible = "mediatek,mt6789-smi-sub-common";
			reg = <0 0x1502f000 0 0x1000>;
			//mediatek,smi = <&smi_sub_comm_img1>;
			// HACK: iommu driver doesn't support tri-level sub-commons for now
			mediatek,smi = <&smi_common_disp>;
			power-domains = <&spm MT6789_POWER_DOMAIN_ISP>;
			clocks = <&imgsys CLK_IMGSYS_LARB9>,
			         <&imgsys CLK_IMGSYS_LARB10>,
			         <&imgsys CLK_IMGSYS_DIP>,
			         <&imgsys CLK_IMGSYS_GALS>;
			clock-names = "apb", "smi", "gals0", "gals1";
		};

		smi_sub_comm_ipe: smi@1b00e000 {
			compatible = "mediatek,mt6789-smi-sub-common";
			reg = <0 0x1b00e000 0 0x1000>;
			//mediatek,smi = <&smi_sub_comm_img1>;
			// HACK: iommu driver doesn't support tri-level sub-commons for now
			mediatek,smi = <&smi_common_disp>;
			power-domains = <&spm MT6789_POWER_DOMAIN_IPE>;
			clocks = <&ipesys CLK_IPE_SMI_SUBCOM>,
			         <&ipesys CLK_IPE_SMI_SUBCOM>,
			         <&ipesys CLK_IPE_SMI_SUBCOM>,
			         <&ipesys CLK_IPE_SMI_SUBCOM>;
			clock-names = "apb", "smi", "gals0", "gals1";
		};

		smi_sub_comm_cam1: smi@1a00c000 {
			compatible = "mediatek,mt6789-smi-sub-common";
			reg = <0 0x1a00c000 0 0x1000>;
			mediatek,smi = <&smi_common_disp>;
			power-domains = <&spm MT6789_POWER_DOMAIN_CAM>;
			clocks = <&camsys CLK_CAM_M_LARB14>,
			         <&camsys CLK_CAM_M_CAM>,
			         <&camsys CLK_CAM_M_LARB14>,
			         <&camsys CLK_CAM_M_CAM>;
			clock-names = "apb", "smi", "gals0", "gals1";
		};

		smi_sub_comm_cam0: smi@1a00d000 {
			compatible = "mediatek,mt6789-smi-sub-common";
			reg = <0 0x1a00d000 0 0x1000>;
			mediatek,smi = <&smi_common_disp>;
			power-domains = <&spm MT6789_POWER_DOMAIN_CAM>;
			clocks = <&camsys CLK_CAM_M_LARB13>,
			         <&camsys CLK_CAM_M_CAM>,
			         <&camsys CLK_CAM_M_LARB13>,
			         <&camsys CLK_CAM_M_CAM>;
			clock-names = "apb", "smi", "gals0", "gals1";
		};

		larb0: smi@14003000 {
			compatible = "mediatek,mt6789-smi-larb";
			mediatek,smi = <&smi_common_disp>;
			reg = <0 0x14003000 0 0x1000>;
			mediatek,larb-id = <0>;
			power-domains = <&spm MT6789_POWER_DOMAIN_DISP>;
			clocks = <&mmsys CLK_MM_SMI_INFRA>,
			         <&mmsys CLK_MM_SMI_COMMON>,
			         <&mmsys CLK_MM_SMI_GALS>,
			         <&mmsys CLK_MM_SMI_IOMMU>;
			clock-names = "apb", "smi", "gals0", "gals1";
		};

		/*iommu0: iommu@14016000 {
			compatible = "mediatek,mt6789-m4u";
			reg = <0 0x14016000 0 0x1000>;
			interrupts = <GIC_SPI 303 IRQ_TYPE_LEVEL_HIGH &ppi_cluster0>;
			mediatek,larbs = <&larb0 &larb1 &larb2
			                  &larb4 &larb7 &larb9
			                  &larb13 &larb14 &larb16
			                  &larb17 &larb20>;
			power-domains = <&spm MT6789_POWER_DOMAIN_DISP>;
			clocks = <&mmsys CLK_MM_SMI_IOMMU>;
			clock-names = "bclk";
			#iommu-cells = <1>;
		};*/

		larb1: smi@14004000 {
			compatible = "mediatek,mt6789-smi-larb";
			mediatek,smi = <&smi_common_disp>;
			reg = <0 0x14004000 0 0x1000>;
			mediatek,larb-id = <1>;
			power-domains = <&spm MT6789_POWER_DOMAIN_DISP>;
			clocks = <&mmsys CLK_MM_SMI_INFRA>,
			         <&mmsys CLK_MM_SMI_COMMON>,
			         <&mmsys CLK_MM_SMI_GALS>,
			         <&mmsys CLK_MM_SMI_IOMMU>;
			clock-names = "apb", "smi", "gals0", "gals1";
		};

		larb2: smi@1f002000 {
			compatible = "mediatek,mt6789-smi-larb";
			mediatek,smi = <&smi_common_disp>;
			reg = <0 0x1f002000 0 0x1000>;
			mediatek,larb-id = <2>;
			power-domains = <&spm MT6789_POWER_DOMAIN_DISP>;
			clocks = <&mdpsys CLK_MDP_SMI0>,
			         <&mdpsys CLK_MDP_SMI0>;
			clock-names = "apb","smi";
		};

		larb4: smi@1602e000 {
			compatible = "mediatek,mt6789-smi-larb";
			mediatek,smi = <&smi_common_disp>;
			reg = <0 0x1602e000 0 0x1000>;
			mediatek,larb-id = <4>;
			power-domains = <&spm MT6789_POWER_DOMAIN_VDEC>;
			clocks = <&vdecsys CLK_VDE2_LARB1_CKEN>,
			         <&vdecsys CLK_VDE2_VDEC_CKEN>;
			clock-names = "apb", "smi";
		};

		larb7: smi@17010000 {
			compatible = "mediatek,mt6789-smi-larb";
			reg = <0 0x17010000 0 0x1000>;
			mediatek,smi = <&smi_common_disp>;
			mediatek,larb-id = <7>;
			power-domains = <&spm MT6789_POWER_DOMAIN_VENC>;
			clocks = <&vencsys CLK_VEN1_CKE0_LARB>,
			         <&vencsys CLK_VEN1_CKE2_JPGENC>;
			clock-names = "apb", "smi";
		};

		larb9: smi@1502e000 {
			compatible = "mediatek,mt6789-smi-larb";
			mediatek,smi = <&smi_sub_comm_img0>;
			reg = <0 0x1502e000 0 0x1000>;
			mediatek,larb-id = <9>;
			power-domains = <&spm MT6789_POWER_DOMAIN_ISP>;
			clocks = <&imgsys CLK_IMGSYS_LARB9>,
			         <&imgsys CLK_IMGSYS_LARB9>;
			clock-names = "apb", "smi";
		};

		larb20: smi@1b00f000 {
			compatible = "mediatek,mt6789-smi-larb";
			reg = <0 0x1b00f000 0 0x1000>;
			mediatek,smi = <&smi_sub_comm_ipe>;
			mediatek,larb-id = <20>;
			power-domains = <&spm MT6789_POWER_DOMAIN_IPE>;
			clocks = <&ipesys CLK_IPE_LARB20>,
			         <&ipesys CLK_IPE_LARB20>;
			clock-names = "apb", "smi";
		};

		larb13: smi@1a001000 {
			compatible = "mediatek,mt6789-smi-larb";
			mediatek,smi = <&smi_sub_comm_cam0>;
			reg = <0 0x1a001000 0 0x1000>;
			mediatek,larb-id = <13>;
			power-domains = <&spm MT6789_POWER_DOMAIN_CAM>;
			clocks = <&camsys CLK_CAM_M_LARB13>,
			         <&camsys CLK_CAM_M_LARB13>;
			clock-names = "apb", "smi";
		};

		larb14: smi@1a002000 {
			compatible = "mediatek,mt6789-smi-larb";
			mediatek,smi = <&smi_sub_comm_cam1>;
			reg = <0 0x1a002000 0 0x1000>;
			mediatek,larb-id = <14>;
			power-domains = <&spm MT6789_POWER_DOMAIN_CAM>;
			clocks = <&camsys CLK_CAM_M_LARB14>,
			         <&camsys CLK_CAM_M_LARB14>;
			clock-names = "apb", "smi";
		};

		larb16: smi@1a00f000 {
			compatible = "mediatek,mt6789-smi-larb";
			mediatek,smi = <&smi_sub_comm_cam1>;
			reg = <0 0x1a00f000 0 0x1000>;
			mediatek,larb-id = <16>;
			power-domains = <&spm MT6789_POWER_DOMAIN_CAM_RAWA>;
			clocks = <&camsys_raw_a CLK_CAM_RA_LARBX>,
			         <&camsys_raw_a CLK_CAM_RA_CAM>;
			clock-names = "apb", "smi";
		};

		larb17: smi@1a010000 {
			compatible = "mediatek,mt6789-smi-larb";
			mediatek,smi = <&smi_sub_comm_cam0>;
			reg = <0 0x1a010000 0 0x1000>;
			mediatek,larb-id = <17>;
			power-domains = <&spm MT6789_POWER_DOMAIN_CAM_RAWB>;
			clocks = <&camsys_raw_b CLK_CAM_RB_LARBX>,
			         <&camsys_raw_b CLK_CAM_RB_CAM>;
			clock-names = "apb", "smi";
		};

		gpu: gpu@13000000 {
			compatible = "mediatek,mt6789-mali", "arm,mali-valhall-jm";
			reg = <0 0x13000000 0 0x4000>;

			clocks = <&mfgcfg CLK_MFGCFG_BG3D>;
			interrupts = <GIC_SPI 398 IRQ_TYPE_LEVEL_HIGH &ppi_cluster0>,
			             <GIC_SPI 397 IRQ_TYPE_LEVEL_HIGH &ppi_cluster0>,
			             <GIC_SPI 396 IRQ_TYPE_LEVEL_HIGH &ppi_cluster0>;
			interrupt-names = "job", "mmu", "gpu";
			operating-points-v2 = <&gpu_opp_table>;
			power-domains = <&spm MT6789_POWER_DOMAIN_MFG2>,
			                <&spm MT6789_POWER_DOMAIN_MFG3>;
			power-domain-names = "core0", "core1";
			#cooling-cells = <2>;
			status = "disabled";
		};

		mipi_tx0: dsi-phy@11f60000 {
			compatible = "mediatek,mt6789-mipi-tx";
			reg = <0 0x11f60000 0 0x1000>;
			clocks = <&clk26m>;
			#clock-cells = <0>;
			#phy-cells = <0>;
			clock-output-names = "mipi_tx0_pll";
		};

		dsi0: dsi@14013000 {
			compatible = "mediatek,mt6789-dsi";
			reg = <0 0x14013000 0 0x1000>;
			interrupts = <GIC_SPI 301 IRQ_TYPE_LEVEL_HIGH &ppi_cluster0>;
			power-domains = <&spm MT6789_POWER_DOMAIN_DISP>;
			clocks = <&mmsys CLK_MM_DSI0>,
			         <&mmsys CLK_MM_DSI0_DSI_CK_DOMAIN>,
			         <&mipi_tx0>;
			clock-names = "engine", "digital", "hs";
			// TODO: Add support for resets in mmsys driver
			//resets = <&mmsys MT6789_MMSYS_SW0_RST_DSI>;
			phys = <&mipi_tx0>;
			phy-names = "dphy";

			ports {
				#address-cells = <1>;
				#size-cells = <0>;

				port@0 {
					reg = <0>;
					dsi0_in: endpoint {
						remote-endpoint = <&dsc0_out>;
					};
				};

				port@1 {
					reg = <1>;
					dsi0_out: endpoint { };
				};
			};
		};

		dsc0: dsc@14012000 {
			compatible = "mediatek,mt6789-disp-dsc";
			reg = <0 0x14012000 0 0x1000>;
			interrupts = <GIC_SPI 300 IRQ_TYPE_LEVEL_HIGH &ppi_cluster0>;
			power-domains = <&spm MT6789_POWER_DOMAIN_DISP>;
			clocks = <&mmsys CLK_MM_DISP_DSC_WRAP0>;
			mediatek,gce-client-reg = <&gce0 SUBSYS_1401XXXX 0x2000 0x1000>;

			ports {
				#address-cells = <1>;
				#size-cells = <0>;

				port@0 {
					reg = <0>;
					dsc0_in: endpoint {
						remote-endpoint = <&dither0_out>;
					};
				};

				port@1 {
					reg = <1>;
					dsc0_out: endpoint {
						remote-endpoint = <&dsi0_in>;
					};
				};
			};
		};

		ovl0: ovl@14005000 {
			compatible = "mediatek,mt6789-disp-ovl", "mediatek,mt8192-disp-ovl";
			reg = <0 0x14005000 0 0x1000>;
			interrupts = <GIC_SPI 287 IRQ_TYPE_LEVEL_HIGH &ppi_cluster0>;
			power-domains = <&spm MT6789_POWER_DOMAIN_DISP>;
			clocks = <&mmsys CLK_MM_DISP_OVL0>;
			mediatek,gce-client-reg = <&gce0 SUBSYS_1400XXXX 0x5000 0x1000>;
			/*iommus = <&iommu0 M4U_PORT_L0_OVL_RDMA0>,
			         <&iommu0 M4U_PORT_L0_OVL_RDMA0_HDR>;*/

			ports {
				#address-cells = <1>;
				#size-cells = <0>;

				port@0 {
					reg = <0>;
					ovl0_in: endpoint { };
				};

				port@1 {
					reg = <1>;
					ovl0_out: endpoint {
						remote-endpoint = <&rdma0_in>;
					};
				};
			};
		};

		ovl_2l0: ovl@14006000 {
			compatible = "mediatek,mt6789-disp-ovl", "mediatek,mt8192-disp-ovl-2l";
			reg = <0 0x14006000 0 0x1000>;
			interrupts = <GIC_SPI 288 IRQ_TYPE_LEVEL_HIGH &ppi_cluster0>;
			power-domains = <&spm MT6789_POWER_DOMAIN_DISP>;
			clocks = <&mmsys CLK_MM_DISP_OVL0_2L>;
			/*iommus = <&iommu0 M4U_PORT_L1_OVL_2L_RDMA0>,
			         <&iommu0 M4U_PORT_L1_OVL_2L_RDMA0_HDR>;*/
			mediatek,gce-client-reg = <&gce0 SUBSYS_1400XXXX 0x6000 0x1000>;
		};

		rdma0: rdma@14007000 {
			compatible = "mediatek,mt6789-disp-rdma";
			reg = <0 0x14007000 0 0x1000>;
			interrupts = <GIC_SPI 289 IRQ_TYPE_LEVEL_HIGH &ppi_cluster0>;
			power-domains = <&spm MT6789_POWER_DOMAIN_DISP>;
			clocks = <&mmsys CLK_MM_DISP_RDMA0>;
			mediatek,rdma-fifo-size = <48992>;
			mediatek,gce-client-reg = <&gce0 SUBSYS_1400XXXX 0x7000 0x1000>;
			/*iommus = <&iommu0 M4U_PORT_L1_DISP_RDMA0>;*/

			ports {
				#address-cells = <1>;
				#size-cells = <0>;

				port@0 {
					reg = <0>;
					rdma0_in: endpoint {
						remote-endpoint = <&ovl0_out>;
					};
				};

				port@1 {
					reg = <1>;
					rdma0_out: endpoint {
						remote-endpoint = <&color0_in>;
					};
				};
			};
		};

		color0: color@14009000 {
			compatible = "mediatek,mt6789-disp-color", "mediatek,mt8173-disp-color";
			reg = <0 0x14009000 0 0x1000>;
			interrupts = <GIC_SPI 291 IRQ_TYPE_LEVEL_HIGH &ppi_cluster0>;
			power-domains = <&spm MT6789_POWER_DOMAIN_DISP>;
			clocks = <&mmsys CLK_MM_DISP_COLOR0>;
			mediatek,gce-client-reg = <&gce0 SUBSYS_1400XXXX 0x9000 0x1000>;

			ports {
				#address-cells = <1>;
				#size-cells = <0>;

				port@0 {
					reg = <0>;
					color0_in: endpoint {
						remote-endpoint = <&rdma0_out>;
					};
				};

				port@1 {
					reg = <1>;
					color0_out: endpoint {
						remote-endpoint = <&dither0_in>;
					};
				};
			};
		};

		ccorr0: ccorr@1400b000 {
			compatible = "mediatek,mt6789-disp-ccorr", "mediatek,mt8183-disp-ccorr";
			reg = <0 0x1400b000 0 0x1000>;
			interrupts = <GIC_SPI 292 IRQ_TYPE_LEVEL_HIGH &ppi_cluster0>;
			power-domains = <&spm MT6789_POWER_DOMAIN_DISP>;
			clocks = <&mmsys CLK_MM_DISP_CCORR0>;
			mediatek,gce-client-reg = <&gce0 SUBSYS_1400XXXX 0xb000 0x1000>;
		};

		aal0: aal@1400c000 {
			compatible = "mediatek,mt6789-disp-aal", "mediatek,mt8183-disp-aal";
			reg = <0 0x1400c000 0 0x1000>;
			interrupts = <GIC_SPI 294 IRQ_TYPE_LEVEL_HIGH &ppi_cluster0>;
			power-domains = <&spm MT6789_POWER_DOMAIN_DISP>;
			clocks = <&mmsys CLK_MM_DISP_AAL0>;
			mediatek,gce-client-reg = <&gce0 SUBSYS_1400XXXX 0xc000 0x1000>;
		};

		gamma0: gamma@1400d000 {
			compatible = "mediatek,mt6789-disp-gamma", "mediatek,mt8195-disp-gamma";
			reg = <0 0x1400d000 0 0x1000>;
			interrupts = <GIC_SPI 295 IRQ_TYPE_LEVEL_HIGH &ppi_cluster0>;
			power-domains = <&spm MT6789_POWER_DOMAIN_DISP>;
			clocks = <&mmsys CLK_MM_DISP_GAMMA0>;
			mediatek,gce-client-reg = <&gce0 SUBSYS_1400XXXX 0xd000 0x1000>;
		};

		postmask0: postmask@1400e000 {
			compatible = "mediatek,mt6789-disp-postmask";
			reg = <0 0x1400e000 0 0x1000>;
			interrupts = <GIC_SPI 296 IRQ_TYPE_LEVEL_HIGH &ppi_cluster0>;
			power-domains = <&spm MT6789_POWER_DOMAIN_DISP>;
			clocks = <&mmsys CLK_MM_DISP_POSTMASK0>;
			/*iommus = <&iommu0 M4U_PORT_L0_DISP_POSTMASK0>;*/
			mediatek,gce-client-reg = <&gce0 SUBSYS_1400XXXX 0xe000 0x1000>;
		};

		dither0: dither@14012000 {
			compatible = "mediatek,mt6789-disp-dither";
			reg = <0 0x1400f000 0 0x1000>;
			interrupts = <GIC_SPI 297 IRQ_TYPE_LEVEL_HIGH &ppi_cluster0>;
			power-domains = <&spm MT6789_POWER_DOMAIN_DISP>;
			clocks = <&mmsys CLK_MM_DISP_DITHER0>;
			mediatek,gce-client-reg = <&gce0 SUBSYS_1400XXXX 0xf000 0x1000>;

			ports {
				#address-cells = <1>;
				#size-cells = <0>;

				port@0 {
					reg = <0>;
					dither0_in: endpoint {
						remote-endpoint = <&color0_out>;
					};
				};

				port@1 {
					reg = <1>;
					dither0_out: endpoint {
						remote-endpoint = <&dsc0_in>;
					};
				};
			};
		};

		usb2: usb@11200000 {
			compatible = "mediatek,mt6789-musb",
			             "mediatek,mtk-musb";
			reg = <0 0x11200000 0 0x10000>;

			status = "disabled";

			interrupts = <GIC_SPI 128 IRQ_TYPE_LEVEL_HIGH &ppi_cluster0>;
			interrupt-names = "mc";

			clocks = <&infracfg_ao CLK_IFRAO_SSUSB>,
			         <&topckgen CLK_TOP_USB_TOP_SEL>,
			         <&apmixedsys CLK_APMIXED_USBPLL>;
			clock-names = "main", "mcu", "univpll";

			phys = <&u2port0 PHY_TYPE_USB2>;
		};

		u2phy: t-phy@11f40000 {
			compatible = "mediatek,mt6789-tphy",
			             "mediatek,generic-tphy-v2";
			#address-cells = <1>;
			#size-cells = <1>;
			ranges = <0 0 0x11f40000 0x1000>;

			u2port0: usb-phy@0 {
				reg = <0x0 0x700>;
				clocks = <&clk26m>;
				clock-names = "ref";
				#phy-cells = <1>;
				mediatek,eye-src = <4>;
				mediatek,eye-vrt = <4>;
				mediatek,eye-term = <4>;
				mediatek,discth = <7>;
			};
		};

		pio: pinctrl@10005000 {
			compatible = "mediatek,mt6789-pinctrl";
			reg = <0 0x10005000 0 0x1000>,
			      <0 0x11c30000 0 0x1000>,
			      <0 0x11d10000 0 0x1000>,
			      <0 0x11d40000 0 0x1000>,
			      <0 0x11e20000 0 0x1000>,
			      <0 0x11e60000 0 0x1000>,
			      <0 0x11ea0000 0 0x1000>,
			      <0 0x1000b000 0 0x1000>;
			reg-names = "base", "rb",  "bm", "br", "lm", "bl",
				    "rt", "eint";
			gpio-controller;
			#gpio-cells = <2>;
			gpio-ranges = <&pio 0 0 188>;
			interrupt-controller;
			interrupts = <GIC_SPI 244 IRQ_TYPE_LEVEL_HIGH &ppi_cluster0>;
			#interrupt-cells = <2>;
		};

		pwm0: pwm@10048000 {
			compatible = "mediatek,mt6789-pwm";
			reg = <0 0x10048000 0 0x1000>;
			interrupts = <GIC_SPI 242 IRQ_TYPE_LEVEL_HIGH &ppi_cluster0>;
			#pwm-cells = <2>;
			clocks = <&topckgen CLK_TOP_PWM_SEL>,
				 <&infracfg_ao CLK_IFRAO_PWM>,
				 <&infracfg_ao CLK_IFRAO_PWM1>,
				 <&infracfg_ao CLK_IFRAO_PWM2>,
				 <&infracfg_ao CLK_IFRAO_PWM3>,
				 <&infracfg_ao CLK_IFRAO_PWM4>;
			clock-names = "top", "main", "pwm1", "pwm2", "pwm3", "pwm4";
		};

		mmc0: mmc@11230000 {
			compatible = "mediatek,mt6789-mmc",
			             "mediatek,mt8183-mmc";
			reg = <0 0x11230000 0 0x10000>,
			      <0 0x11f50000 0 0x1000>;

			interrupts = <GIC_SPI 131 IRQ_TYPE_LEVEL_HIGH &ppi_cluster0>;

			clocks = <&topckgen CLK_TOP_MSDC50_0_SEL>,
			         <&infracfg_ao CLK_IFRAO_MSDC0>,
			         <&infracfg_ao CLK_IFRAO_MSDC0_SRC>;

			clock-names = "source", "hclk", "source_cg";

			status = "disabled";
		};

		mmc1: mmc@11240000 {
			compatible = "mediatek,mt6789-mmc",
			             "mediatek,mt8183-mmc";
			reg = <0 0x11240000 0 0x1000>,
			      <0 0x11ef0000 0 0x1000>;

			interrupts = <GIC_SPI 135 IRQ_TYPE_LEVEL_HIGH &ppi_cluster0>;

			clocks = <&topckgen CLK_TOP_MSDC30_1_SEL>,
			         <&infracfg_ao CLK_IFRAO_MSDC1>,
			         <&infracfg_ao CLK_IFRAO_MSDC1_SRC>;
			clock-names = "source", "hclk", "source_cg";

			status = "disabled";
		};

		pwrap: pmic-wrapper@10026000 {
			compatible = "mediatek,mt6789-pwrap", "syscon";
			reg = <0 0x10026000 0 0x1000>;
			reg-names = "pwrap";
			interrupts = <GIC_SPI 252 IRQ_TYPE_LEVEL_HIGH &ppi_cluster0>;
			clocks = <&infracfg_ao CLK_IFRAO_PMIC_AP>,
			         <&infracfg_ao CLK_IFRAO_PMIC_TMR>;
			assigned-clocks = <&topckgen CLK_TOP_PWRAP_ULPOSC_SEL>;
			assigned-clock-parents = <&topckgen CLK_TOP_OSC_D10>;
		};

		ufsphy: ufs-phy@11fa0000 {
			compatible = "mediatek,mt6789-ufsphy",
			             "mediatek,mt8183-ufsphy";
			reg = <0 0x01fa0000 0 0xc000>;
			clocks = <&infracfg_ao CLK_IFRAO_UNIPRO_SYSCLK>,
			         <&infracfg_ao CLK_IFRAO_UFS_SAP_BCLK>;
			clock-names = "unipro", "mp";
			#phy-cells = <0>;

			status = "disabled";
		};

		ufs: ufs@11270000 {
			compatible = "mediatek,mt6789-ufshci",
			             "mediatek,mt8183-ufshci";
			reg = <0 0x11270000 0 0x2300>;
			interrupts = <GIC_SPI 137 IRQ_TYPE_LEVEL_HIGH &ppi_cluster0>;
			phys = <&ufsphy>;

			status = "disabled";

			clocks = <&infracfg_ao CLK_IFRAO_UFS>,
			         <&topckgen CLK_TOP_UFS_SEL>;
			clock-names = "ufs", "ufs_sel";
			freq-table-hz = <0 0>, <0 0>;

			resets = <&infracfg_ao MT6789_INFRA_RST1_UFSHCI_SWRST>,
			         <&infracfg_ao MT6789_INFRA_RST2_UNIPRO_SWRST>,
			         <&infracfg_ao MT6789_INFRA_RST3_UFS_CRYPTO_SWRST>;
			reset-names = "hci_rst", "unipro_rst", "crypto_rst";

			mediatek,ufs-disable-mcq;
			mediatek,ufs-broken-vcc;
		};

		disp_pwm0: pwm@1100e000 {
			compatible = "mediatek,mt6789-disp-pwm";
			reg = <0 0x1100e000 0 0x1000>;
			interrupts = <GIC_SPI 203 IRQ_TYPE_LEVEL_HIGH &ppi_cluster0>;
			#pwm-cells = <2>;
			clocks = <&infracfg_ao CLK_IFRAO_DISP_PWM>,
			         <&topckgen CLK_TOP_DISP_PWM_SEL>;
			clock-names = "main", "mm";
		};

		apdma: dma-controller@10217800 {
			compatible = "mediatek,mt6789-uart-dma",
			             "mediatek,mt6577-uart-dma";
			reg = <0 0x10217800 0 0x80>,
			      <0 0x10217880 0 0x80>,
			      <0 0x10217900 0 0x80>,
			      <0 0x10217980 0 0x80>;
			interrupts = <GIC_SPI 178 IRQ_TYPE_LEVEL_HIGH &ppi_cluster0>,
			             <GIC_SPI 179 IRQ_TYPE_LEVEL_HIGH &ppi_cluster0>,
			             <GIC_SPI 180 IRQ_TYPE_LEVEL_HIGH &ppi_cluster0>,
			             <GIC_SPI 181 IRQ_TYPE_LEVEL_HIGH &ppi_cluster0>;
			dma-requests = <4>;
			clocks = <&infracfg_ao CLK_IFRAO_AP_DMA>;
			clock-names = "apdma";
			#dma-cells = <1>;
		};

		uart0: serial@11002000 {
			compatible = "mediatek,mt6789-uart",
			             "mediatek,mt6577-uart";
			reg = <0 0x11002000 0 0x1000>;
			interrupts = <GIC_SPI 141 IRQ_TYPE_LEVEL_HIGH &ppi_cluster0>;
			clocks = <&clk26m>, <&infracfg_ao CLK_IFRAO_UART0>;
			clock-names = "baud", "bus";
			dmas = <&apdma 0 &apdma 1>;
			dma-names = "tx", "rx";
			status = "disabled";
		};

		uart1: serial@11003000 {
			compatible = "mediatek,mt6789-uart",
			             "mediatek,mt6577-uart";
			reg = <0 0x11003000 0 0x1000>;
			interrupts = <GIC_SPI 142 IRQ_TYPE_LEVEL_HIGH &ppi_cluster0>;
			clocks = <&clk26m>, <&infracfg_ao CLK_IFRAO_UART1>;
			clock-names = "baud", "bus";
			dmas = <&apdma 2 &apdma 3>;
			dma-names = "tx", "rx";
			status = "disabled";
		};

		i2c0: i2c@11e00000 {
			compatible = "mediatek,mt6789-i2c",
			             "mediatek,mt8188-i2c";
			reg = <0 0x11e00000 0 0x1000>,
			      <0 0x10217080 0 0x80>;

			interrupts = <GIC_SPI 144 IRQ_TYPE_LEVEL_HIGH &ppi_cluster0>;

			clocks = <&imp_iic_wrap_w CLK_IMP_IIC_WRAP_W_AP_CLOCK_I2C0>,
			         <&infracfg_ao CLK_IFRAO_AP_DMA>;
			clock-names = "main", "dma";
			clock-div = <1>;

			#address-cells = <1>;
			#size-cells = <0>;

			status = "disabled";
		};

		i2c1: i2c@11e01000 {
			compatible = "mediatek,mt6789-i2c",
			             "mediatek,mt8188-i2c";
			reg = <0 0x11e01000 0 0x1000>,
			      <0 0x10217100 0 0x80>;

			interrupts = <GIC_SPI 145 IRQ_TYPE_LEVEL_HIGH &ppi_cluster0>;

			clocks = <&imp_iic_wrap_w CLK_IMP_IIC_WRAP_W_AP_CLOCK_I2C1>,
			         <&infracfg_ao CLK_IFRAO_AP_DMA>;
			clock-names = "main", "dma";
			clock-div = <1>;

			#address-cells = <1>;
			#size-cells = <0>;

			status = "disabled";
		};

		i2c2: i2c@11eb0000 {
			compatible = "mediatek,mt6789-i2c",
			             "mediatek,mt8188-i2c";
			reg = <0 0x11eb0000 0 0x1000>,
			      <0 0x10217180 0 0x80>;

			interrupts = <GIC_SPI 146 IRQ_TYPE_LEVEL_HIGH &ppi_cluster0>;

			clocks = <&imp_iic_wrap_en CLK_IMP_IIC_WRAP_EN_AP_CLOCK_I2C2>,
			         <&infracfg_ao CLK_IFRAO_AP_DMA>;
			clock-names = "main", "dma";
			clock-div = <1>;

			#address-cells = <1>;
			#size-cells = <0>;

			status = "disabled";
		};

		i2c3: i2c@11015000 {
			compatible = "mediatek,mt6789-i2c",
			             "mediatek,mt8188-i2c";
			reg = <0 0x11015000 0 0x1000>,
			      <0 0x10217280 0 0x80>;

			interrupts = <GIC_SPI 147 IRQ_TYPE_LEVEL_HIGH &ppi_cluster0>;

			clocks = <&imp_iic_wrap_c CLK_IMP_IIC_WRAP_C_AP_CLOCK_I2C3>,
			         <&infracfg_ao CLK_IFRAO_AP_DMA>;

			clock-names = "main", "dma";
			clock-div = <1>;

			#address-cells = <1>;
			#size-cells = <0>;

			status = "disabled";
		};

		i2c4: i2c@11eb1000 {
			compatible = "mediatek,mt6789-i2c",
			             "mediatek,mt8188-i2c";
			reg = <0 0x11eb1000 0 0x1000>,
			      <0 0x10217300 0 0x80>;

			interrupts = <GIC_SPI 148 IRQ_TYPE_LEVEL_HIGH &ppi_cluster0>;

			clocks = <&imp_iic_wrap_en CLK_IMP_IIC_WRAP_EN_AP_CLOCK_I2C4>,
			         <&infracfg_ao CLK_IFRAO_AP_DMA>;
			clock-names = "main", "dma";
			clock-div = <1>;

			#address-cells = <1>;
			#size-cells = <0>;

			status = "disabled";
		};

		i2c5: i2c@11017000 {
			compatible = "mediatek,mt6789-i2c",
			             "mediatek,mt8188-i2c";
			reg = <0 0x11017000 0 0x1000>,
			      <0 0x10217400 0 0x80>;

			interrupts = <GIC_SPI 149 IRQ_TYPE_LEVEL_HIGH &ppi_cluster0>;

			clocks = <&imp_iic_wrap_c CLK_IMP_IIC_WRAP_C_AP_CLOCK_I2C5>,
			         <&infracfg_ao CLK_IFRAO_AP_DMA>;
			clock-names = "main", "dma";
			clock-div = <1>;

			#address-cells = <1>;
			#size-cells = <0>;

			status = "disabled";
		};

		i2c6: i2c@1101a000 {
			compatible = "mediatek,mt6789-i2c",
			             "mediatek,mt8188-i2c";
			reg = <0 0x1101a000 0 0x1000>,
			      <0 0x10217480 0 0x80>;

			interrupts = <GIC_SPI 150 IRQ_TYPE_LEVEL_HIGH &ppi_cluster0>;

			clocks = <&imp_iic_wrap_c CLK_IMP_IIC_WRAP_C_AP_CLOCK_I2C6>,
			         <&infracfg_ao CLK_IFRAO_AP_DMA>;
			clock-names = "main", "dma";
			clock-div = <1>;

			#address-cells = <1>;
			#size-cells = <0>;

			status = "disabled";
		};

		i2c7: i2c@11f00000 {
			compatible = "mediatek,mt6789-i2c",
			             "mediatek,mt8188-i2c";
			reg = <0 0x11f00000 0 0x1000>,
			      <0 0x10217500 0 0x80>;

			interrupts = <GIC_SPI 151 IRQ_TYPE_LEVEL_HIGH &ppi_cluster0>;

			clocks = <&imp_iic_wrap_n CLK_IMP_IIC_WRAP_N_AP_CLOCK_I2C7>,
			         <&infracfg_ao CLK_IFRAO_AP_DMA>;
			clock-names = "main", "dma";
			clock-div = <1>;

			#address-cells = <1>;
			#size-cells = <0>;

			status = "disabled";
		};

		i2c8: i2c@11eb2000 {
			compatible = "mediatek,mt6789-i2c",
			             "mediatek,mt8188-i2c";
			reg = <0 0x11eb2000 0 0x1000>,
			      <0 0x10217600 0 0x80>;

			interrupts = <GIC_SPI 152 IRQ_TYPE_LEVEL_HIGH &ppi_cluster0>;

			clocks = <&imp_iic_wrap_en CLK_IMP_IIC_WRAP_EN_AP_CLOCK_I2C8>,
			         <&infracfg_ao CLK_IFRAO_AP_DMA>;
			clock-names = "main", "dma";
			clock-div = <1>;

			#address-cells = <1>;
			#size-cells = <0>;

			status = "disabled";
		};

		i2c9: i2c@11eb3000 {
			compatible = "mediatek,mt6789-i2c",
			             "mediatek,mt8188-i2c";
			reg = <0 0x11eb3000 0 0x1000>,
			      <0 0x10217700 0 0x80>;

			interrupts = <GIC_SPI 153 IRQ_TYPE_LEVEL_HIGH &ppi_cluster0>;

			clocks = <&imp_iic_wrap_en CLK_IMP_IIC_WRAP_EN_AP_CLOCK_I2C9>,
			         <&infracfg_ao CLK_IFRAO_AP_DMA>;
			clock-names = "main", "dma";
			clock-div = <1>;

			#address-cells = <1>;
			#size-cells = <0>;

			status = "disabled";
		};

		spi0: spi@1100a000 {
			compatible = "mediatek,mt6789-spi",
			             "mediatek,mt6893-spi";
			mediatek,pad-select = <0>;

			reg = <0 0x1100a000 0 0x100>;

			interrupts = <GIC_SPI 191 IRQ_TYPE_LEVEL_HIGH &ppi_cluster0>;

			clocks = <&topckgen CLK_TOP_MSDCPLL_D2>,
			         <&topckgen CLK_TOP_SPI_SEL>,
			         <&infracfg_ao CLK_IFRAO_SPI0>;
			clock-names = "parent-clk", "sel-clk", "spi-clk";

			#address-cells = <1>;
			#size-cells = <0>;

			status = "disabled";
		};

		spi1: spi@11010000 {
			compatible = "mediatek,mt6789-spi",
			             "mediatek,mt6893-spi";
			mediatek,pad-select = <0>;

			reg = <0 0x11010000 0 0x100>;

			interrupts = <GIC_SPI 192 IRQ_TYPE_LEVEL_HIGH &ppi_cluster0>;

			clocks = <&topckgen CLK_TOP_MSDCPLL_D2>,
			         <&topckgen CLK_TOP_SPI_SEL>,
			         <&infracfg_ao CLK_IFRAO_SPI1>;
			clock-names = "parent-clk", "sel-clk", "spi-clk";

			#address-cells = <1>;
			#size-cells = <0>;

			status = "disabled";
		};

		spi2: spi@11012000 {
			compatible = "mediatek,mt6789-spi",
			             "mediatek,mt6893-spi";
			mediatek,pad-select = <0>;

			reg = <0 0x11012000 0 0x100>;

			interrupts = <GIC_SPI 193 IRQ_TYPE_LEVEL_HIGH &ppi_cluster0>;

			clocks = <&topckgen CLK_TOP_MSDCPLL_D2>,
			         <&topckgen CLK_TOP_SPI_SEL>,
			         <&infracfg_ao CLK_IFRAO_SPI2>;
			clock-names = "parent-clk", "sel-clk", "spi-clk";

			#address-cells = <1>;
			#size-cells = <0>;

			status = "disabled";
		};

		spi3: spi@11013000 {
			compatible = "mediatek,mt6789-spi",
			             "mediatek,mt6893-spi";
			mediatek,pad-select = <0>;

			reg = <0 0x11013000 0 0x100>;

			interrupts = <GIC_SPI 194 IRQ_TYPE_LEVEL_HIGH &ppi_cluster0>;

			clocks = <&topckgen CLK_TOP_MSDCPLL_D2>,
			         <&topckgen CLK_TOP_SPI_SEL>,
			         <&infracfg_ao CLK_IFRAO_SPI3>;
			clock-names = "parent-clk", "sel-clk", "spi-clk";

			#address-cells = <1>;
			#size-cells = <0>;

			status = "disabled";
		};

		spi4: spi@11018000 {
			compatible = "mediatek,mt6789-spi",
			             "mediatek,mt6893-spi";
			mediatek,pad-select = <0>;

			reg = <0 0x11018000 0 0x100>;

			interrupts = <GIC_SPI 195 IRQ_TYPE_LEVEL_HIGH &ppi_cluster0>;

			clocks = <&topckgen CLK_TOP_MSDCPLL_D2>,
			         <&topckgen CLK_TOP_SPI_SEL>,
			         <&infracfg_ao CLK_IFRAO_SPI4>;
			clock-names = "parent-clk", "sel-clk", "spi-clk";

			#address-cells = <1>;
			#size-cells = <0>;
			status = "disabled";
		};

		spi5: spi@11019000 {
			compatible = "mediatek,mt6789-spi",
			             "mediatek,mt6893-spi";
			mediatek,pad-select = <0>;
			reg = <0 0x11019000 0 0x100>;
			interrupts = <GIC_SPI 196 IRQ_TYPE_LEVEL_HIGH &ppi_cluster0>;
			clocks = <&topckgen CLK_TOP_MSDCPLL_D2>,
			         <&topckgen CLK_TOP_SPI_SEL>,
			         <&infracfg_ao CLK_IFRAO_SPI5>;
			clock-names = "parent-clk", "sel-clk", "spi-clk";
			#address-cells = <1>;
			#size-cells = <0>;
			status = "disabled";
		};
	};
};
